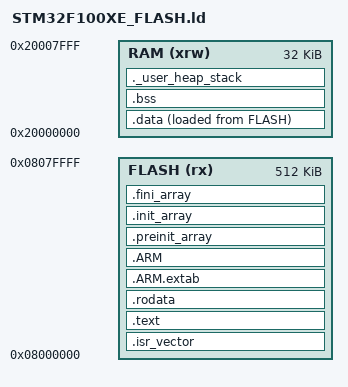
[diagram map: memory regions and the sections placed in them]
/*
*****************************************************************************
**
**  File        : STM32F100XE_FLASH.ld
**
**  Abstract    : Linker script for STM32F100xE Device with
**                512KByte FLASH, 32KByte RAM
**
**                Set heap size, stack size and stack location according
**                to application requirements.
**
**                Set memory bank area and size if external memory is used.
**
**  Target      : STMicroelectronics STM32
**
**  Environment : Atollic TrueSTUDIO(R)
**
**  Distribution: The file is distributed “as is,” without any warranty
**                of any kind.
**
**  (c)Copyright Atollic AB.
**  You may use this file as-is or modify it according to the needs of your
**  project. This file may only be built (assembled or compiled and linked)
**  using the Atollic TrueSTUDIO(R) product. The use of this file together
**  with other tools than Atollic TrueSTUDIO(R) is not permitted.
**
*****************************************************************************
*/
0
/* Entry Point */
ENTRY(Reset_Handler)
0
/* Highest address of the user mode stack */
_estack = 0x20007FFF;    /* end of RAM */
0
/* Generate a link error if heap and stack don't fit into RAM */
_Min_Heap_Size = 0x200;      /* required amount of heap  */
_Min_Stack_Size = 0x400; /* required amount of stack */
0
/* Specify the memory areas */
MEMORY
{
FLASH (rx)      : ORIGIN = 0x08000000, LENGTH = 512K
RAM (xrw)       : ORIGIN = 0x20000000, LENGTH = 32K
}
0
/* Define output sections */
SECTIONS
{
  /* The startup code goes first into FLASH */
  .isr_vector :
  {
    . = ALIGN(4);
    KEEP(*(.isr_vector)) /* Startup code */
    . = ALIGN(4);
  } >FLASH
0
  /* The program code and other data goes into FLASH */
  .text :
  {
    . = ALIGN(4);
    *(.text)           /* .text sections (code) */
    *(.text*)          /* .text* sections (code) */
    *(.glue_7)         /* glue arm to thumb code */
    *(.glue_7t)        /* glue thumb to arm code */
    *(.eh_frame)
0
    KEEP (*(.init))
    KEEP (*(.fini))
0
    . = ALIGN(4);
    _etext = .;        /* define a global symbols at end of code */
  } >FLASH
0
  /* Constant data goes into FLASH */
  .rodata :
  {
    . = ALIGN(4);
    *(.rodata)         /* .rodata sections (constants, strings, etc.) */
    *(.rodata*)        /* .rodata* sections (constants, strings, etc.) */
    . = ALIGN(4);
  } >FLASH
0
  .ARM.extab   : { *(.ARM.extab* .gnu.linkonce.armextab.*) } >FLASH
  .ARM : {
    __exidx_start = .;
    *(.ARM.exidx*)
    __exidx_end = .;
  } >FLASH
0
  .preinit_array     :
  {
    PROVIDE_HIDDEN (__preinit_array_start = .);
    KEEP (*(.preinit_array*))
    PROVIDE_HIDDEN (__preinit_array_end = .);
  } >FLASH
  .init_array :
  {
    PROVIDE_HIDDEN (__init_array_start = .);
    KEEP (*(SORT(.init_array.*)))
    KEEP (*(.init_array*))
    PROVIDE_HIDDEN (__init_array_end = .);
  } >FLASH
  .fini_array :
  {
    PROVIDE_HIDDEN (__fini_array_start = .);
    KEEP (*(SORT(.fini_array.*)))
    KEEP (*(.fini_array*))
    PROVIDE_HIDDEN (__fini_array_end = .);
  } >FLASH
0
  /* used by the startup to initialize data */
  _sidata = LOADADDR(.data);
0
  /* Initialized data sections goes into RAM, load LMA copy after code */
  .data : 
  {
    . = ALIGN(4);
    _sdata = .;        /* create a global symbol at data start */
    *(.data)           /* .data sections */
    *(.data*)          /* .data* sections */
0
    . = ALIGN(4);
    _edata = .;        /* define a global symbol at data end */
  } >RAM AT> FLASH
0
  
  /* Uninitialized data section */
  . = ALIGN(4);
  .bss :
  {
    /* This is used by the startup in order to initialize the .bss secion */
    _sbss = .;         /* define a global symbol at bss start */
    __bss_start__ = _sbss;
    *(.bss)
    *(.bss*)
    *(COMMON)
0
    . = ALIGN(4);
    _ebss = .;         /* define a global symbol at bss end */
    __bss_end__ = _ebss;
  } >RAM
0
  /* User_heap_stack section, used to check that there is enough RAM left */
  ._user_heap_stack :
  {
    . = ALIGN(4);
    PROVIDE ( end = . );
    PROVIDE ( _end = . );
    . = . + _Min_Heap_Size;
    . = . + _Min_Stack_Size;
    . = ALIGN(4);
  } >RAM
0
  
0
  /* Remove information from the standard libraries */
  /DISCARD/ :
  {
    libc.a ( * )
    libm.a ( * )
    libgcc.a ( * )
  }
0
  .ARM.attributes 0 : { *(.ARM.attributes) }
}
